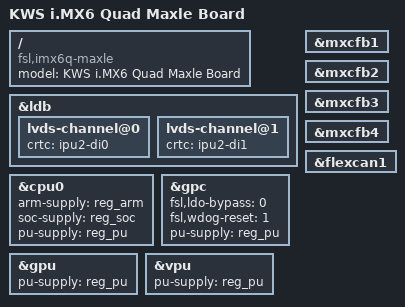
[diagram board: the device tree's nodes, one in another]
/*
 * Copyright 2012 Freescale Semiconductor, Inc.
 * Copyright 2011 Linaro Ltd.
 *
 * The code contained herein is licensed under the GNU General Public
 * License. You may obtain a copy of the GNU General Public License
 * Version 2 or later at the following locations:
 *
 * http://www.opensource.org/licenses/gpl-license.html
 * http://www.gnu.org/copyleft/gpl.html
 */

/dts-v1/;

#include "imx6q.dtsi"
#include "imx6qdl-maxle.dtsi"

/ {
	model = "KWS i.MX6 Quad Maxle Board";
	compatible = "fsl,imx6q-maxle", "fsl,imx6q", "hannstar,cabc";
};

/*
&battery {
	offset-charger = <1900>;
	offset-discharger = <1694>;
	offset-usb-charger = <1685>;
};
*/

&ldb {    // maxle wiwi 53 neu
	lvds-channel@0 {
		crtc = "ipu2-di0";
	};

	lvds-channel@1 {
		crtc = "ipu2-di1";
	};
};

&mxcfb1 {
	status = "okay";
};

&mxcfb2 {
	status = "okay";
};

&mxcfb3 {
	status = "okay";
};

&mxcfb4 {
	status = "okay";
};

&flexcan1{
	status = "okay";
};

#if 0
&crypto{
	status = "disabled";
};
#endif

/****************************************/
/* for maxle we add                     */
/****************************************/

&cpu0 {
	arm-supply = <&reg_arm>;
	soc-supply = <&reg_soc>;
	pu-supply = <&reg_pu>; /* use pu_dummy if VDDSOC share with VDDPU */
};

&gpc {
	fsl,ldo-bypass = <0>; /* use ldo-bypass, u-boot will check it and configure */
	fsl,wdog-reset = <1>; /* watchdog select of reset source */
	pu-supply = <&reg_pu>; /* ldo-bypass:use pu_dummy if VDDSOC share with VDDPU */
};

&gpu {
	pu-supply = <&reg_pu>; /* ldo-bypass:use pu_dummy if VDDSOC share with VDDPU */
};

&vpu {
	pu-supply = <&reg_pu>; /* ldo-bypass:use pu_dummy if VDDSOC share with VDDPU */
};
